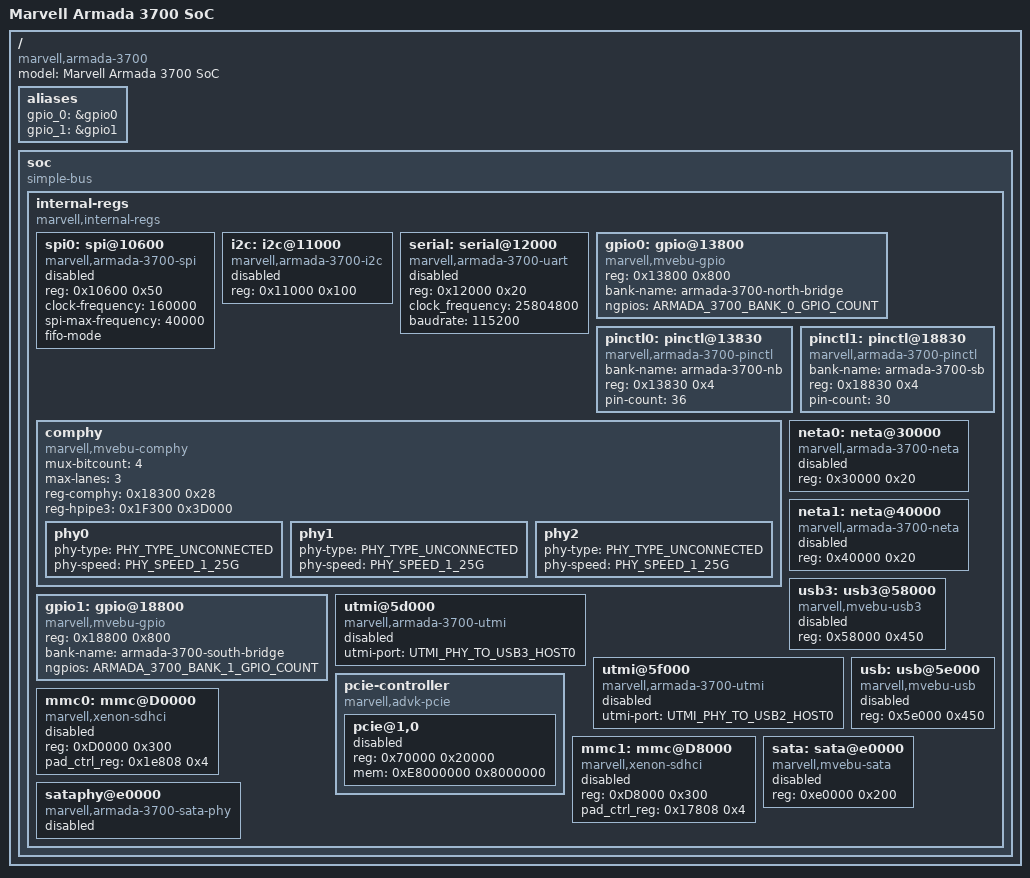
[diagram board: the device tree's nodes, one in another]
#define ATTR(remapped, target, attributes) (((remapped) << 12) | ((target) << 8) | (attributes))
#define IO_ATTR(win_attr, max_win, max_remap, remap_size, win_offset) (((win_attr) << 24) | ((max_win) << 20) | ((max_remap) << 16) | ((remap_size) << 8) | (win_offset))

#include <dt-bindings/comphy/comphy_data.h>
#include <dt-bindings/gpio/armada-3700-gpio.h>
/ {
	model = "Marvell Armada 3700 SoC";
	compatible = "marvell,armada-3700";
	#address-cells = <2>;
	#size-cells = <2>;

	aliases {
		gpio_0 = &gpio0;
		gpio_1 = &gpio1;
	};

	soc {
		compatible = "simple-bus";
		#address-cells = <1>;
		#size-cells = <0>;

		internal-regs {
			compatible = "marvell,internal-regs", "simple-bus";
			#address-cells = <1>;
			#size-cells = <1>;
			ranges = <0x0000 0xd0000000 0x2000000>;

			spi0: spi@10600 {
				compatible = "marvell,armada-3700-spi";
				reg = <0x10600 0x50>;
				#clock-cells = <0>;
				clock-frequency = <160000>;
				spi-max-frequency = <40000>;
				fifo-mode;
				status = "disabled";
			};

			i2c: i2c@11000 {
				compatible = "marvell,armada-3700-i2c", "simple-bus";
				#address-cells = <1>;
				#size-cells = <0>;

				reg = <0x11000 0x100>;
				status = "disabled";
			};

			serial: serial@12000 {
				compatible = "marvell,armada-3700-uart";
				reg = <0x12000 0x20>;
				clock_frequency = <25804800>;
				baudrate = <115200>;
				status = "disabled";
			};
			gpio0: gpio@13800 {
				compatible = "marvell,mvebu-gpio";
				reg = <0x13800 0x800>;
				bank-name = "armada-3700-north-bridge";
				ngpios = <ARMADA_3700_BANK_0_GPIO_COUNT>;
				status = "okay";
			};

			pinctl0: pinctl@13830 { /* north bridge */
				compatible = "marvell,armada-3700-pinctl";
				bank-name = "armada-3700-nb";
				reg = <0x13830 0x4>;
				pin-count = <36>;
			};

			comphy {
				compatible = "marvell,mvebu-comphy", "marvell,comphy-armada-3700";
				mux-bitcount = <4>;
				max-lanes = <3>;
				reg-comphy = <0x18300 0x28>;
				reg-hpipe3 = <0x1F300 0x3D000>;
				/* phy-type & phy-speed selection should be done in board level device tree */
				phy0 {
					phy-type = <PHY_TYPE_UNCONNECTED>;
					phy-speed = <PHY_SPEED_1_25G>;
				};
				phy1 {
					phy-type = <PHY_TYPE_UNCONNECTED>;
					phy-speed = <PHY_SPEED_1_25G>;
				};
				phy2 {
					phy-type = <PHY_TYPE_UNCONNECTED>;
					phy-speed = <PHY_SPEED_1_25G>;
				};
			};
			gpio1: gpio@18800 {
				compatible = "marvell,mvebu-gpio";
				reg = <0x18800 0x800>;
				bank-name = "armada-3700-south-bridge";
				ngpios = <ARMADA_3700_BANK_1_GPIO_COUNT>;
				status = "okay";
			};
			pinctl1: pinctl@18830 { /* south bridge */
				compatible = "marvell,armada-3700-pinctl";
				bank-name = "armada-3700-sb";
				reg = <0x18830 0x4>;
				pin-count = <30>;
			};

			neta0: neta@30000 {
				compatible = "marvell,armada-3700-neta";
				reg = <0x30000 0x20>;
				status = "disabled";
			};
			neta1: neta@40000 {
				compatible = "marvell,armada-3700-neta";
				reg = <0x40000 0x20>;
				status = "disabled";
			};
			usb3: usb3@58000 {
				compatible = "marvell,mvebu-usb3";
				reg = <0x58000 0x450>;
				status = "disabled";
			};
			utmi@5d000 {
				compatible = "marvell,armada-3700-utmi";
				utmi-port = <UTMI_PHY_TO_USB3_HOST0>;
				status = "disabled";
			};
			utmi@5f000 {
				compatible = "marvell,armada-3700-utmi";
				utmi-port = <UTMI_PHY_TO_USB2_HOST0>;
				status = "disabled";
			};
			/* no concurrent support for USB2.0 and USB3.0 now
			 * Need to disable the XHCI driver and enable EHCI
			 * driver before turn on USB2.0 interface.
			 */
			usb: usb@5e000 {
				compatible = "marvell,mvebu-usb";
				reg = <0x5e000 0x450>;
				status = "disabled";
			};
			pcie-controller {
				#address-cells = <1>;
				#size-cells = <1>;
				compatible = "marvell,advk-pcie";

				pcie@1,0 {
					reg = <0x70000 0x20000>;
					mem = <0xE8000000 0x8000000>;
					status = "disabled";
				};
			};
			mmc0: mmc@D0000 {
				compatible = "marvell,xenon-sdhci";
				reg = <0xD0000 0x300>;
				pad_ctrl_reg = <0x1e808 0x4>;
				status = "disabled";
			};
			mmc1: mmc@D8000 {
				compatible = "marvell,xenon-sdhci";
				reg = <0xD8000 0x300>;
				pad_ctrl_reg = <0x17808 0x4>;
				status = "disabled";
			};
			sata: sata@e0000 {
				compatible = "marvell,mvebu-sata";
				reg = <0xe0000 0x200>;
				status = "disabled";
			};
			sataphy@e0000 {
				compatible = "marvell,armada-3700-sata-phy";
				status = "disabled";
			};
		};
	};
};
